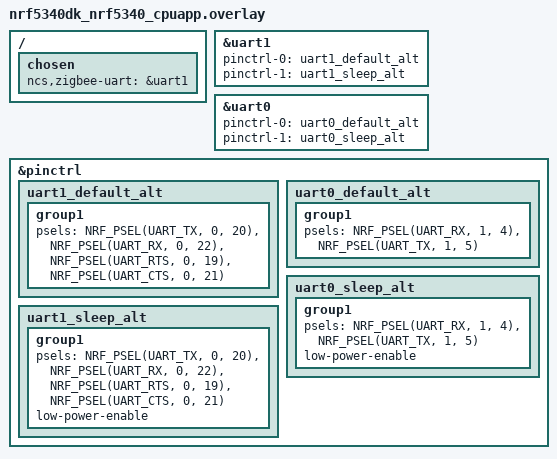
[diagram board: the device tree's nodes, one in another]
/*
 * Copyright (c) 2021-2022 Nordic Semiconductor ASA
 *
 * SPDX-License-Identifier: LicenseRef-Nordic-5-Clause
 */

&uart1 {
	status = "okay";
	pinctrl-0 = <&uart1_default_alt>;
	pinctrl-1 = <&uart1_sleep_alt>;
	pinctrl-names = "default", "sleep";
};

&uart0 {
	pinctrl-0 = <&uart0_default_alt>;
	pinctrl-1 = <&uart0_sleep_alt>;
	pinctrl-names = "default", "sleep";
};

/ {
	chosen {
		ncs,zigbee-uart = &uart1;
	};
};

&pinctrl {
	uart1_default_alt: uart1_default_alt {
		group1 {
			psels = <NRF_PSEL(UART_TX, 0, 20)>,
				<NRF_PSEL(UART_RX, 0, 22)>,
				<NRF_PSEL(UART_RTS, 0, 19)>,
				<NRF_PSEL(UART_CTS, 0, 21)>;
		};
	};

	uart1_sleep_alt: uart1_sleep_alt {
		group1 {
			psels = <NRF_PSEL(UART_TX, 0, 20)>,
				<NRF_PSEL(UART_RX, 0, 22)>,
				<NRF_PSEL(UART_RTS, 0, 19)>,
				<NRF_PSEL(UART_CTS, 0, 21)>;
			low-power-enable;
		};
	};

	uart0_default_alt: uart0_default_alt {
		group1 {
			psels = <NRF_PSEL(UART_RX, 1, 4)>,
				<NRF_PSEL(UART_TX, 1, 5)>;
		};
	};

	uart0_sleep_alt: uart0_sleep_alt {
		group1 {
			psels = <NRF_PSEL(UART_RX, 1, 4)>,
				<NRF_PSEL(UART_TX, 1, 5)>;
			low-power-enable;
		};
	};

};
